# TestCoalesce register map
Series: JetBrains; File version: 1.0.0
CPU: CM0 r0p0, big endian, no MPU, no FPU, 2 interrupt priority bits
Registers are 8-bit, read-write, reset 0x0 unless marked. A register's access mark holds for its fields unless they carry their own. Offsets are from the block's base; lines under a group give offsets from that group; [hi:lo] are bit positions; {n}, {i} and the like mark numbered series; 'fields as' and 'values as' point back to an identical list; <NAME> marks a mode.

## Memory map
0x00001000 P1 — GPIO Controller
0x00001000 P2 — GPIO Controller

## P1 — GPIO Controller
Base 0x00001000
0x02 R3 16-bit — Blah-blah
0x15 R1 32-bit (reset mask 0x3FFFFFF) — Blah-blah
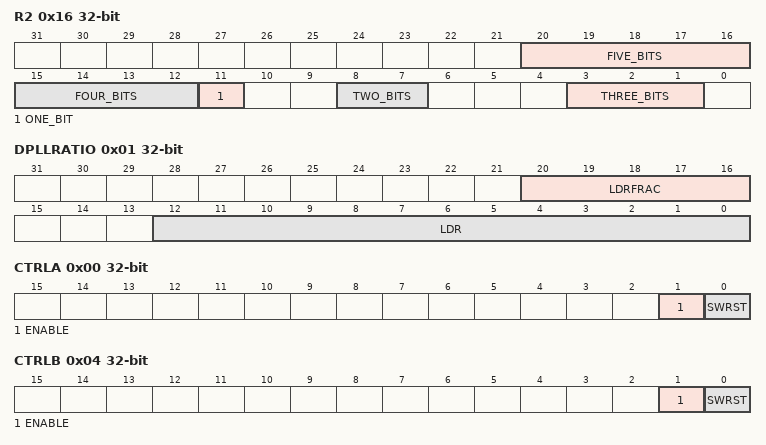
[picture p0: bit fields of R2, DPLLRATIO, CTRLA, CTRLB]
0x16 R2 32-bit — Blah-blah
  [20:16] FIVE_BITS
  [15:12] FOUR_BITS
  [11] ONE_BIT
  [8:7] TWO_BITS
  [3:1] THREE_BITS
    on write: 0=PAD0 (SERCOM PAD[0] is used as data input); 1=PAD1 (SERCOM PAD[1] is used as data input); 2=PAD2 (SERCOM PAD[2] is used as data input); other=PAD3 (SERCOM PAD[3] is used as data input)
0x30 DPLL group
  0x00 DPLLCTRLA reset 0x80 — DPLL Control A
    [7] ONDEMAND — On Demand Control
  0x01 DPLLRATIO 32-bit — DPLL Ratio Control
    [20:16] LDRFRAC — Loop Divider Ratio Fractional Part
    [12:0] LDR — Loop Divider Ratio
  0x10 USART_EXT group (alternate view of I2CM) — USART EXTERNAL CLOCK Mode
    0x00 CTRLA 32-bit — USART_EXT Control A
      [1] ENABLE
      [0] SWRST — Software Reset
    0x04 CTRLB 32-bit ro — USART_EXT Control B
      [1] ENABLE
      [0] SWRST — Software Reset

## P2 — GPIO Controller
Base 0x00001000
{0x13+2i} R[{i}] (i=0..1) 16-bit — Blah-blah
{0x130+2i} CLS1[{i}] (i=0..1) group
  0x00 R1 reset 0x80 — Test reg
  0x01 R11 reset 0x80 — Test reg
0x140 CLS2_{x} (x=B,C,D; step 0x2) group
  0x00 R2 reset 0x80 — Test reg
{0x126+2i} CLS3_{i} (i=21..22) group
  0x00 R3 reset 0x80 — Test reg
0x160 CLS4_{x} (x=A,B,C; step 0x2) group
  0x00 R3 reset 0x80 — Test reg
